VERSION ""

NS_ :

BS_:

BU_: CLUSTER AIRBAG

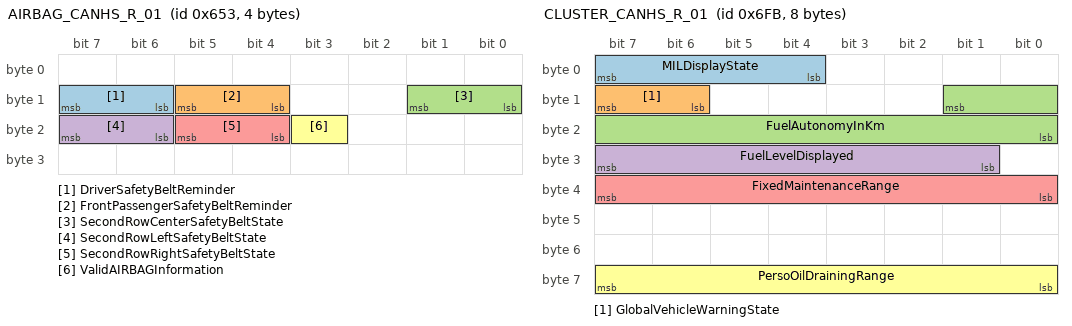
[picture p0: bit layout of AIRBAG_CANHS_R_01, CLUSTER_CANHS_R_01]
BO_ 1619 AIRBAG_CANHS_R_01: 4 AIRBAG
 SG_ DriverSafetyBeltReminder : 15|2@0+ (1,0) [0|0] ""  CLUSTER
 SG_ FrontPassengerSafetyBeltReminder : 13|2@0+ (1,0) [0|0] ""  CLUSTER
 SG_ SecondRowCenterSafetyBeltState : 9|2@0+ (1,0) [0|0] ""  CLUSTER
 SG_ SecondRowLeftSafetyBeltState : 23|2@0+ (1,0) [0|0] ""  CLUSTER
 SG_ SecondRowRightSafetyBeltState : 21|2@0+ (1,0) [0|0] ""  CLUSTER
 SG_ ValidAIRBAGInformation : 19|1@0+ (1,0) [0|0] ""  CLUSTER

BO_ 1787 CLUSTER_CANHS_R_01: 8 CLUSTER
 SG_ MILDisplayState : 7|4@0+ (1,0) [0|0] "" Vector__XXX
 SG_ GlobalVehicleWarningState : 15|2@0+ (1,0) [0|0] "" Vector__XXX
 SG_ FuelAutonomyInKm : 9|10@0+ (1,0) [0|1022] "km" Vector__XXX
 SG_ FuelLevelDisplayed : 31|7@0+ (1,0) [0|80] "l" Vector__XXX
 SG_ FixedMaintenanceRange : 39|8@0+ (250,0) [0|63250] "km" Vector__XXX
 SG_ PersoOilDrainingRange : 63|8@0+ (250,0) [0|63500] "km" Vector__XXX

BA_DEF_  "Baudrate" INT 0 1000000;
BA_DEF_  "BusType" STRING ;
BA_DEF_  "NmType" STRING ;
BA_DEF_  "Manufacturer" STRING ;
BA_DEF_  "DBName" STRING ;
BA_DEF_ BO_  "CycleTime" INT 0 10000;
BA_DEF_ BO_  "FrameType" STRING ;
BA_DEF_DEF_  "Baudrate" 0;
BA_DEF_DEF_  "BusType" "";
BA_DEF_DEF_  "NmType" "";
BA_DEF_DEF_  "Manufacturer" "";
BA_DEF_DEF_  "DBName" "";
BA_DEF_DEF_  "CycleTime" 100;
BA_DEF_DEF_  "FrameType" "-";
BA_ "Manufacturer" "SAMPLE";
BA_ "NmType" "Sample Specific";
BA_ "BusType" "CAN";
BA_ "Baudrate" 500000;
BA_ "DBName" "SAMPLE_DB_V1_0";
BA_ "FrameType" BO_ 1619 "Periodic";
BA_ "CycleTime" BO_ 1787 3000;
BA_ "FrameType" BO_ 1787 "Periodic";
